# KM1M7CF14 register map
Vendor: Nuvoton Technology Corporation Japan; Series: KM1M7CF; File version: 1.0.3
CPU: CM7 r1p2, little endian, MPU, FPU, double-precision FPU, I-cache, D-cache, ITCM, DTCM, 4 interrupt priority bits
Registers are 32-bit, read-write, no defined reset value unless marked. A register's access mark holds for its fields unless they carry their own. Offsets are from the block's base; [hi:lo] are bit positions; {n}, {i} and the like mark numbered series.

## SMBUS — SMBus Interface
Base 0x40050300
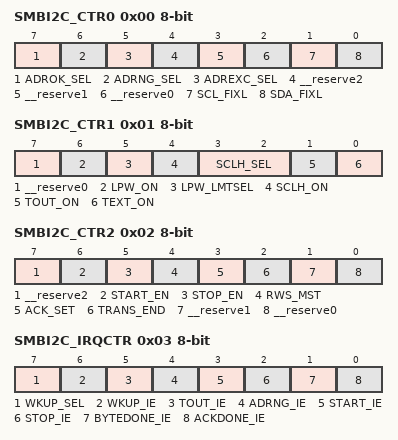
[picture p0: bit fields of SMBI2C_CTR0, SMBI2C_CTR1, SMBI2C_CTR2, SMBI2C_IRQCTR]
0x00 SMBI2C_CTR0 8-bit access per field — SMBus/IIC Control Register 0
  [7] ADROK_SEL rw — Slave address receive mode selection (*1) (*3)
  [6] ADRNG_SEL rw — Slave address receive mode selection (*1) (*3)
  [5] ADREXC_SEL rw — Extension code matching operation select (*1) (*2) (*3)
  [4] __reserve2 ro — "0" is always read out.
  [3] __reserve1 rw — This bit must be set to "0".
  [2] __reserve0 ro — "0" is always read out.
  [1] SCL_FIXL rw — SMCL port LOW level output (*3)
  [0] SDA_FIXL rw — SMDA port LOW level output (*3)
0x01 SMBI2C_CTR1 8-bit access per field — SMBus/IIC Control Register 1
  [7] __reserve0 ro — "0" is always read out.
  [6] LPW_ON rw — Bus stop detection enable (*1)
  [5] LPW_LMTSEL rw — Bus stop detection period (*1)
  [4] SCLH_ON rw — Clock "High-level" period (THIGH) detection enable (*1)
  [3:2] SCLH_SEL rw — Clock "High-level" period detection time (*1)
  [1] TOUT_ON rw — Clock "Low-level" period (TTIMEOUT) detection enable (*1)
  [0] TEXT_ON rw — TLOW:MEXT / TLOW:SEXT detection enable (*1)
0x02 SMBI2C_CTR2 8-bit access per field — SMBus/IIC Control Register 2
  [7] __reserve2 ro — "0" is always read out.
  [6] START_EN rw — Start condition generation selection (*1) (*4)
  [5] STOP_EN rw — Stop condition generation selection (*2) (*4)
  [4] RWS_MST rw — Read/Write mode selection at Master (*3) (*4)
  [3] ACK_SET rw — Transmission ACK bit selection (*4)
  [2] TRANS_END rw — Communication end setting (*4)
  [1] __reserve1 ro — "0" is always read out.
  [0] __reserve0 ro — "0" is always read out.
0x03 SMBI2C_IRQCTR 8-bit — SMBus/IIC Interrupt Control Register
  [7] WKUP_SEL — Interrupt source selection for exiting CPU standby mode (*5)
  [6] WKUP_IE — Enable CPU WAKEUP interrupt factor (*1) (*5)
  [5] TOUT_IE — Enable Time-out interrupt factor (*5)
  [4] ADRNG_IE — Enable Slave address mismatch interrupt factor (*5)
  [3] START_IE — Enable Start condition detection interrupt factor (*5)
  [2] STOP_IE — Enable Stop condition interrupt factor (*5)
  [1] BYTEDONE_IE — Enable Byte data communication completion interrupt factor (*2) (*3) (*5)
  [0] ACKDONE_IE — Enable ACK communication completion interrupt factor (*4) (*5)
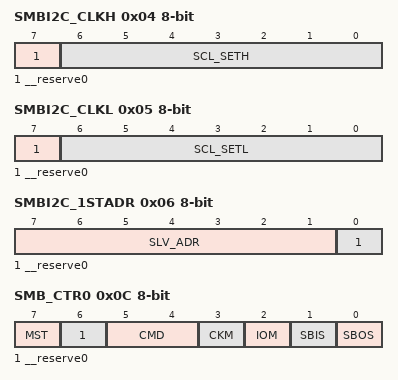
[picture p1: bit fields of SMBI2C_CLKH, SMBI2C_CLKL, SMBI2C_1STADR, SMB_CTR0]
0x04 SMBI2C_CLKH 8-bit access per field — SMBus/IIC Clock High Level Frequency Setting Register
  [7] __reserve0 ro — "0" is always read out.
  [6:0] SCL_SETH rw — High level period of transfer clock at master communication (*1) (*2) (*3)
0x05 SMBI2C_CLKL 8-bit access per field — SMBus/IIC Clock Low Level Frequency Setting Register
  [7] __reserve0 ro — "0" is always read out.
  [6:0] SCL_SETL rw — Low level period of transfer clock at master communication (*1) (*2) (*3)
0x06 SMBI2C_1STADR 8-bit access per field — SMBus/IIC Slave Address Setting Register
  [7:1] SLV_ADR rw — Set the slave address. (*1) (*2)
  [0] __reserve0 ro — "0" is always read out.
0x07 SMBI2C_TCLKOC 8-bit — SMBus/IIC Timeout Clock Compare Register
  [7:0] TCLKOC — Time-out clock source division counter compare setting (*1) (*2)
0x0C SMB_CTR0 8-bit access per field — SMBus control register 0
  [7] MST rw — Master/Slave communication selection
  [6] __reserve0 ro — "0" is always read out.
  [5:4] CMD rw — Communication mode selection (*1)
  [3] CKM rw — Division selection of transfer clock
  [2] IOM rw — Data input pin selection (*2)
  [1] SBIS rw — SMDA pin input control (*2)
  [0] SBOS rw — SMDA pin output control (*2)
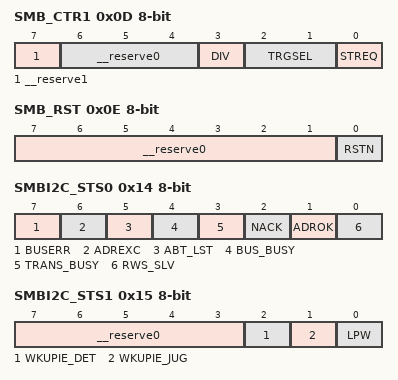
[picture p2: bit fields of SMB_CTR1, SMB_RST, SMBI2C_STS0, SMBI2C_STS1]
0x0D SMB_CTR1 8-bit access per field — SMBus control register 1
  [7] __reserve1 ro — "0" is always read out.
  [6:4] __reserve0 rw — This bit must be set to "111".
  [3] DIV rw — Division value selection of transfer clock
  [2:1] TRGSEL rw — Selection of communication start factor(*1)
  [0] STREQ ro — Communication start trigger by software (*1) (*2)
0x0E SMB_RST 8-bit access per field — SMBus Reset Register
  [7:1] __reserve0 ro — "0x00" is always read out.
  [0] RSTN rw — [SMBus / IIC]
0x10 SMBRB 8-bit ro — SMBus Reception Data Buffer Register
  [7:0] RB — Reception data is read out.
0x12 SMBTB 8-bit — SMBus Transmission Data Buffer Register
  [7:0] TB — Set the transmission data or the dummy data.
0x14 SMBI2C_STS0 8-bit access per field — SMBus/IIC Status Register 0
  [7] BUSERR rw — Bus error detection (*1)
  [6] ADREXC ro — Extension code receive detection
  [5] ABT_LST rw — Arbitration lost detection (*1)
  [4] BUS_BUSY ro — Bus busy state detection (*2)
  [3] TRANS_BUSY ro — Communication busy state detection (*3)
  [2] NACK ro — NACK detection
  [1] ADROK ro — Slave address matching detection
  [0] RWS_SLV ro — Read/ Write mode determination at Master/Slave communication (*4)
0x15 SMBI2C_STS1 8-bit ro — SMBus/IIC Status Register 1
  [7:3] __reserve0 — "0" is always read out.
  [2] WKUPIE_DET — CPU WAKEUP interrupt status
  [1] WKUPIE_JUG — WKUP interrupt judgement
  [0] LPW — Bus stop detection
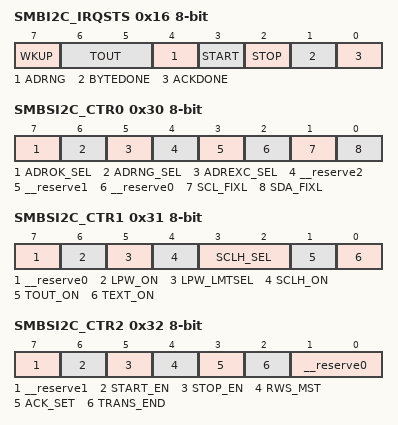
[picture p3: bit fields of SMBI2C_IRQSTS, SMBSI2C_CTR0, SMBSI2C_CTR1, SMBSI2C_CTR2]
0x16 SMBI2C_IRQSTS 8-bit access per field — SMBus/IIC Interrupt Status Register
  [7] WKUP rw — SMBus/IIC standby status exit detection (*1) (*2)
  [6:5] TOUT ro — Time-out detection (*2)
  [4] ADRNG rw — Slave address mismatch detection (*1) (*2)
  [3] START rw — Start condition detection (*1) (*2) (*3)
  [2] STOP rw — Stop condition detection (*1) (*2)
  [1] BYTEDONE rw — Byte data communication completion detection (*1) (*2)
  [0] ACKDONE rw — ACK communication completion detection (*1) (*2)
0x30 SMBSI2C_CTR0 8-bit wo — SMBus/IIC Control Set Register 0
  [7] ADROK_SEL — Set SMBI2C_CTR0.ADROK_SEL bit to "1"
  [6] ADRNG_SEL — Set SMBI2C_CTR0.ADRNG_SEL bit to "1"
  [5] ADREXC_SEL — Set SMBI2C_CTR0.ADREXC_SEL bit to "1"
  [4] __reserve2 — This bit must be set to "0".
  [3] __reserve1 — This bit must be set to "0".
  [2] __reserve0 — This bit must be set to "0".
  [1] SCL_FIXL — Set SMBI2C_CTR0.SCL_FIXL bit to "1"
  [0] SDA_FIXL — Set SMBI2C_CTR0.SDA_FIXL bit to "1"
0x31 SMBSI2C_CTR1 8-bit wo — SMBus/IIC Control Set Register 1
  [7] __reserve0 — This bit must be set to "0".
  [6] LPW_ON — Set SMBI2C_CTR1.LPW_ONL bit to "1"
  [5] LPW_LMTSEL — Set SMBI2C_CTR1.LPW_LMTSEL bit to "1"
  [4] SCLH_ON — Set SMBI2C_CTR1.SCLH_ON bit to "1"
  [3:2] SCLH_SEL — Set SMBI2C_CTR1.SCLH_SEL bit to "1"
  [1] TOUT_ON — Set SMBI2C_CTR1.TOUT_ON bit to "1"
  [0] TEXT_ON — Set SMBI2C_CTR1.TEXT_ON bit to "1"
0x32 SMBSI2C_CTR2 8-bit wo — SMBus/IIC Control Set Register 2
  [7] __reserve1 — This bit must be set to "0".
  [6] START_EN — Set SMBI2C_CTR2.START_EN bit to "1".
  [5] STOP_EN — Set SMBI2C_CTR2.STOP_EN bit to "1".
  [4] RWS_MST — Set SMBI2C_CTR2.RWS_MST bit to "1".
  [3] ACK_SET — Set SMBI2C_CTR2.ACK_SET bit to "1".
  [2] TRANS_END — Set SMBI2C_CTR2.TRANS_END bit to "1".
  [1:0] __reserve0 — This bit must be set to "0".
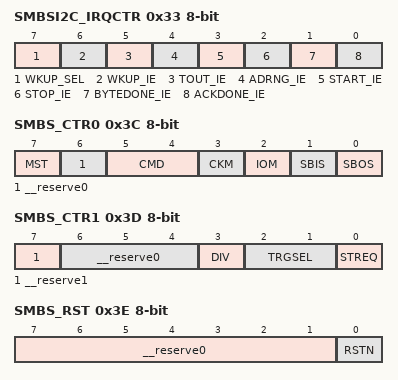
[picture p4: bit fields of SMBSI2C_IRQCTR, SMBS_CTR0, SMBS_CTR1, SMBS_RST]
0x33 SMBSI2C_IRQCTR 8-bit wo — SMBus/IIC Interrupt Control Set Register
  [7] WKUP_SEL — Set SMBI2C_IRQCTR.WKUP_SEL bit to "1".
  [6] WKUP_IE — Set SMBI2C_IRQCTR.WKUP_IE bit to "1".
  [5] TOUT_IE — Set SMBI2C_IRQCTR.TOUT_IE bit to "1".
  [4] ADRNG_IE — Set SMBI2C_IRQCTR.ADRNG_IE bit to "1".
  [3] START_IE — Set SMBI2C_IRQCTR.START_IE bit to "1".
  [2] STOP_IE — Set SMBI2C_IRQCTR.STOP_IE bit to "1".
  [1] BYTEDONE_IE — Set SMBI2C_IRQCTR.BYTEDONE_IE bit to "1".
  [0] ACKDONE_IE — Set SMBI2C_IRQCTR.ACKDONE_IE bit to "1".
0x3C SMBS_CTR0 8-bit wo — SMBus Control Set Register 0
  [7] MST — Set SMB_CTR0.MST bit to "1".
  [6] __reserve0 — This bit must be set to "0".
  [5:4] CMD — This bit must be set to "00".
  [3] CKM — Set SMB_CTR0.CKM bit to "1".
  [2] IOM — Set SMB_CTR0.IOM bit to "1".
  [1] SBIS — Set SMB_CTR0.SBIS bit to "1".
  [0] SBOS — Set SMB_CTR0.SBOS bit to "1".
0x3D SMBS_CTR1 8-bit wo — SMBus Control Set Register 1
  [7] __reserve1 — This bit must be set to "0".
  [6:4] __reserve0 — This bit must be set to "000".
  [3] DIV — Set SMB_CTR1.DIV bit to "1".
  [2:1] TRGSEL — This bit must be set to "00".
  [0] STREQ — Communication start trigger by software (*1) (*2)
0x3E SMBS_RST 8-bit wo — SMBus Reset Set Register
  [7:1] __reserve0 — This bit must be set to "0x00".
  [0] RSTN — Set SMB_RST.RSTN bit to "1"
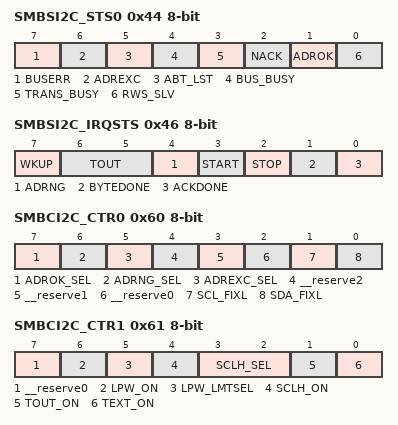
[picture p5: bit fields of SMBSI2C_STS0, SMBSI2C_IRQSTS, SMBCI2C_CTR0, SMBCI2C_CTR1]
0x44 SMBSI2C_STS0 8-bit wo — SMBus/IIC Status Set Register 0
  [7] BUSERR — Clear SMBI2C_STS0.BUSERR bit to "0".
  [6] ADREXC — This bit must be set to "0".
  [5] ABT_LST — Clear SMBI2C_STS0.ABT_LST bit to "0".
  [4] BUS_BUSY — This bit must be set to "0".
  [3] TRANS_BUSY — This bit must be set to "0".
  [2] NACK — This bit must be set to "0".
  [1] ADROK — This bit must be set to "0".
  [0] RWS_SLV — This bit must be set to "0".
0x46 SMBSI2C_IRQSTS 8-bit wo — SMBus/IIC Interrupt Clear Status Register
  [7] WKUP — Clear SMBI2C_IRQSTS.WKUP bit to "0".
  [6:5] TOUT — This bit must be set to "00".
  [4] ADRNG — Clear SMBI2C_IRQSTS.ADRNG bit to "0".
  [3] START — Clear SMBI2C_IRQSTS.START bit to "0".
  [2] STOP — Clear SMBI2C_IRQSTS.STOP bit to "0".
  [1] BYTEDONE — Clear SMBI2C_IRQSTS.BYREDONE bit to "0".
  [0] ACKDONE — Clear SMBI2C_IRQSTS.ACKDONE bit to "0".
0x60 SMBCI2C_CTR0 8-bit wo — SMBus/IIC Control Clear Register 0
  [7] ADROK_SEL — Clear SMBI2C_CTR0.ADROK_SEL bit to "0"
  [6] ADRNG_SEL — Clear SMBI2C_CTR0.ADRNG_SEL bit to "0"
  [5] ADREXC_SEL — Clear SMBI2C_CTR0.ADREXC_SEL bit to "0"
  [4] __reserve2 — This bit must be set to "0".
  [3] __reserve1 — This bit must be set to "0".
  [2] __reserve0 — This bit must be set to "0".
  [1] SCL_FIXL — Clear SMBI2C_CTR0.SCL_FIXL bit to "0"
  [0] SDA_FIXL — Clear SMBI2C_CTR0.SDA_FIXL bit to "0"
0x61 SMBCI2C_CTR1 8-bit wo — SMBus/IIC Control Clear Register 1
  [7] __reserve0 — This bit must be set to "0".
  [6] LPW_ON — Clear SMBI2C_CTR1.LPW_ONL bit to "0"
  [5] LPW_LMTSEL — Clear SMBI2C_CTR1.LPW_LMTSEL bit to "0".
  [4] SCLH_ON — Clear SMBI2C_CTR1.SCLH_ON bit to "0".
  [3:2] SCLH_SEL — Clear SMBI2C_CTR1.SCLH_SEL bit to "0".
  [1] TOUT_ON — Clear SMBI2C_CTR1.TOUT_ON bit to "0".
  [0] TEXT_ON — Clear SMBI2C_CTR1.TEXT_ON bit to "0".
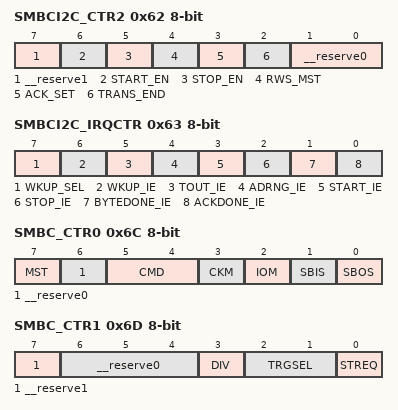
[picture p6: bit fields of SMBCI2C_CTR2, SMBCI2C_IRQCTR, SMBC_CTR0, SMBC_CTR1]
0x62 SMBCI2C_CTR2 8-bit wo — SMBus/IIC Control Clear Register 2
  [7] __reserve1 — This bit must be set to "0".
  [6] START_EN — Set SMBI2C_CTR2.START_EN bit to "0".
  [5] STOP_EN — Set SMBI2C_CTR2.STOP_EN bit to "0".
  [4] RWS_MST — Set SMBI2C_CTR2.RWS_MST bit to "0".
  [3] ACK_SET — Set SMBI2C_CTR2.ACK_SET bit to "0".
  [2] TRANS_END — Set SMBI2C_CTR2.TRANS_END bit to "0".
  [1:0] __reserve0 — This bit must be set to "0".
0x63 SMBCI2C_IRQCTR 8-bit wo — SMBus/IIC Interrupt Control Clear Register
  [7] WKUP_SEL — Clear SMBI2C_IRQCTR.WKUP_SEL bit to "0".
  [6] WKUP_IE — Clear SMBI2C_IRQCTR.WKUP_IE bit to "0".
  [5] TOUT_IE — Clear SMBI2C_IRQCTR.TOUT_IE bit to "0".
  [4] ADRNG_IE — Clear SMBI2C_IRQCTR.ADRNG_IE bit to "0".
  [3] START_IE — Clear SMBI2C_IRQCTR.START_IE bit to "0".
  [2] STOP_IE — Clear SMBI2C_IRQCTR.STOP_IE bit to "0".
  [1] BYTEDONE_IE — Clear SMBI2C_IRQCTR.BYTEDONE_IE bit to "0".
  [0] ACKDONE_IE — Clear SMBI2C_IRQCTR.ACKDONE_IE bit to "0".
0x6C SMBC_CTR0 8-bit wo — SMBus Control Clear Register 0
  [7] MST — Clear SMB_CTR0.MST bit to "0".
  [6] __reserve0 — This bit must be set to "0".
  [5:4] CMD — This bit must be set to "00".
  [3] CKM — Clear SMB_CTR0.CKM bit to "0".
  [2] IOM — Clear SMB_CTR0.IOM bit to "0".
  [1] SBIS — Clear SMB_CTR0.SBIS bit to "0".
  [0] SBOS — Clear SMB_CTR0.SBOS bit to "0".
0x6D SMBC_CTR1 8-bit wo — SMBus Control Clear Register 1
  [7] __reserve1 — This bit must be set to "0".
  [6:4] __reserve0 — This bit must be set to "000".
  [3] DIV — Clear SMB_CTR1.DIV bit to "0".
  [2:1] TRGSEL — This bit must be set to "00".
  [0] STREQ — This bit must be set to "0".
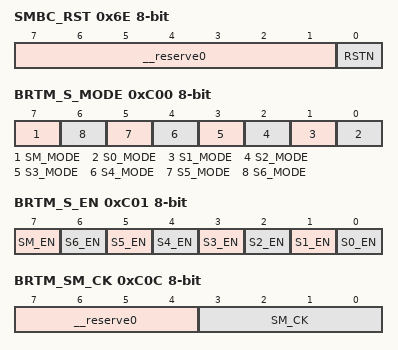
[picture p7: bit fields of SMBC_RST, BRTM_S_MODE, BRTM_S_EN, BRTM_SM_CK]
0x6E SMBC_RST 8-bit wo — SMBus Reset Clear Register
  [7:1] __reserve0 — This bit must be set to "0x00".
  [0] RSTN — Clear SMB_RST.RSTN bit to "0"
0xC00 BRTM_S_MODE 8-bit — Baud Rate Timer Operation Mode Setting Register
  [7] SM_MODE — Setting of baud rate timer SMBus output clock duty (High-level : Low-level)
  [n] S{n}_MODE (n=0..6) — Setting of baud rate timer {n} output clock duty (High-level : Low-level)
0xC01 BRTM_S_EN 8-bit — Baud Rate Timer Operation Enable Register
  [7] SM_EN — Baud rate timer SMBus operation enable
  [n] S{n}_EN (n=0..6) — Baud rate timer {n} operation enable
0xC0C BRTM_SM_CK 8-bit access per field — Baud Rate Timer M Count Clock Selection Register
  [7:4] __reserve0 ro — 0 is always read out.
  [3:0] SM_CK rw — Selection of count clock in baud rate timer SMBus
0xC1D BRTM_SM_OC 8-bit — Baud Rate Timer M Compare Register
  [7:0] SM_OC — Set the value to be compared with the counter of baud rate timer.
